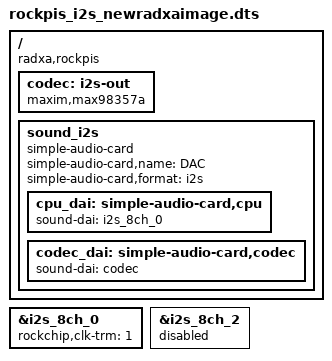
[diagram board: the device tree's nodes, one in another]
// Definitions for i2s-output
/dts-v1/;
/plugin/;

/ {
        compatible = "radxa,rockpis", "rockchip,rk3308";

        fragment@0 {
                target = <&i2s_8ch_0>;
                
                __overlay__ {
                        #sound-dai-cells = <0>;
                        rockchip,clk-trm = <1>;
                        status = "okay";
                        };
               };
               
        fragment@1 {
                target = <&i2s_8ch_2>;
                
                __overlay__ {
                        #sound-dai-cells = <0>;
                        status = "disabled";
                        };
               };

        fragment@2 {
                target-path = "/";
                
                __overlay__ {
                        codec: i2s-out {
                                #sound-dai-cells = <0>;
                                compatible = "maxim,max98357a";
                                status = "okay";
                                };
                        
                        sound_i2s {
                                simple-audio-card,name = "DAC";
                                compatible = "simple-audio-card";
                                simple-audio-card,format = "i2s";
                                status = "okay";
                                
                                cpu_dai: simple-audio-card,cpu {
                                sound-dai = <&i2s_8ch_0>;
                                };
                                
                                codec_dai: simple-audio-card,codec {
                                sound-dai = <&codec>;
                                };
                         };
                };
        };
};
